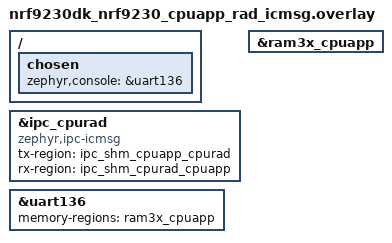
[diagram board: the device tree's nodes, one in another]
/*
 * Copyright (c) 2023 Nordic Semiconductor ASA
 *
 * SPDX-License-Identifier: Apache-2.0
 */

#include <common/nordic_nrf_next/nrfx_ram3x_dma.dtsi>

/{
	chosen {
		zephyr,console = &uart136;
	};
};

&ipc_cpurad {
	compatible = "zephyr,ipc-icmsg";
	tx-region = <&ipc_shm_cpuapp_cpurad>;
	rx-region = <&ipc_shm_cpurad_cpuapp>;
	status = "okay";
	/delete-property/ memory-region;
	/delete-property/ role;
};

ipc0: &ipc_cpurad { };

/* ram3x_cpuapp buffer is used by App core UART driver. */
&ram3x_cpuapp {
	status = "okay";
};

&uart136 {
	status = "okay";
	memory-regions = <&ram3x_cpuapp>;
};
